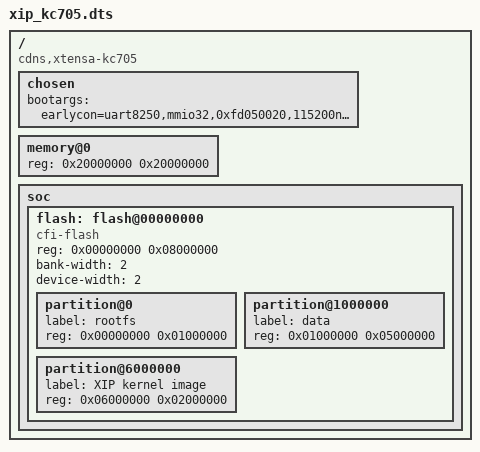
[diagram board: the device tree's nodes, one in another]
// SPDX-License-Identifier: GPL-2.0
/dts-v1/;
/include/ "kc705.dts"

/ {
	compatible = "cdns,xtensa-kc705";
	chosen {
		bootargs = "earlycon=uart8250,mmio32,0xfd050020,115200n8 console=ttyS0,115200n8 debug rw root=mtd:rootfs";
	};
	memory@0 {
		device_type = "memory";
		reg = <0x20000000 0x20000000>;
	};
	soc {
		flash: flash@00000000 {
			#address-cells = <1>;
			#size-cells = <1>;
			compatible = "cfi-flash";
			reg = <0x00000000 0x08000000>;
			bank-width = <2>;
			device-width = <2>;
			partition@0 {
				label = "rootfs";
				reg = <0x00000000 0x01000000>;
			};
			partition@1000000 {
				label = "data";
				reg = <0x01000000 0x05000000>;
			};
			partition@6000000 {
				label = "XIP kernel image";
				reg = <0x06000000 0x02000000>;
			};
		};
	};
};
